# apollo4p register map
Vendor: Ambiq Micro; Series: Apollo; File version: 1.0
CPU: CM4 r1p0, little endian, MPU, FPU, 3 interrupt priority bits
Registers are 32-bit, read-write, reset 0x0 unless marked. A register's access mark holds for its fields unless they carry their own. Offsets are from the block's base; [hi:lo] are bit positions; {n}, {i} and the like mark numbered series; 'fields as' and 'values as' point back to an identical list.

## ADC — Analog Digital Converter Control
Base 0x40038000
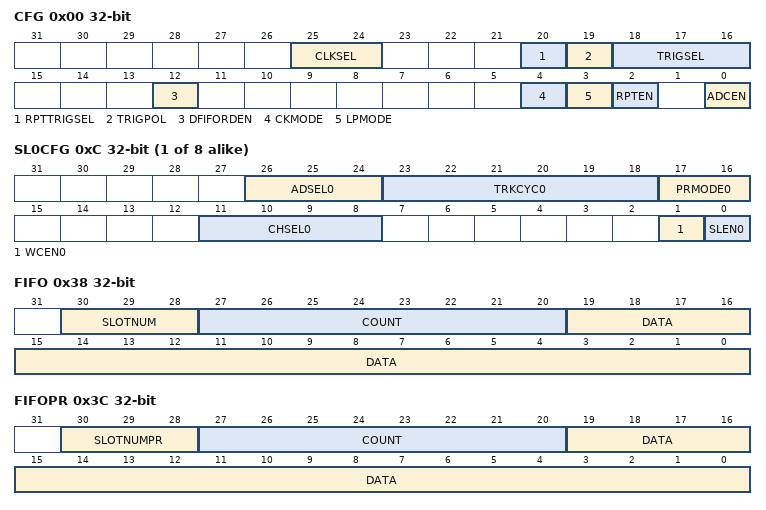
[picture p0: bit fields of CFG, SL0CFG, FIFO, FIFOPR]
0x00 CFG — The ADC Configuration Register contains the software control for selecting the clock frequency used for the SAR conversions, the trigger polarity, the trigger select, the reference voltage select, the low power mode, the operating mode (single scan per trigger vs. repeating mode) and ADC enable.
  [25:24] CLKSEL — Select the source and frequency for the ADC clock. HFRC_48MHz is the only valid clock selection and can be selected by either of 2 field values; the reset default of 0 or by the value 1. All values enumerated below as 'RESVD' are undefined. The ADC controller automatically shuts off the clock in its low power modes. When setting ADCEN to '0', CLKSEL should remain set to 0x0 or 0x1 for proper power down sequencing.
    0=HFRC_48MHZ (HFRC Clock 48MHz.); 1=HFRC_48MHZ1 (HFRC Clock 48MHz. Note that the preferred setting is HFRC_48MHZ (0).)
  [20] RPTTRIGSEL — This bit selects which periodic trigger to use with RPTEN = 1.
    0=TMR (Trigger from on-chip timer.); 1=INT (Trigger from ADC-internal timer.)
  [19] TRIGPOL — This bit selects the ADC trigger polarity for external off chip triggers.
    0=RISING_EDGE (Trigger on rising edge.); 1=FALLING_EDGE (Trigger on falling edge.)
  [18:16] TRIGSEL — Select the ADC trigger source.
    {v}=EXT{v} (Off chip External Trigger{v} (ADC_ET{v})) (v=0..3); 4=VCOMP (Voltage Comparator Output); 7=SWT (Software Trigger)
  [12] DFIFORDEN — Destructive FIFO Read Enable. Setting this will enable FIFO pop upon reading the FIFOPR register.
    0=DIS (Destructive Reads are prevented. Reads to the FIFOPR register will not POP an entry off the FIFO.); 1=EN (Reads to the FIFOPR registger will automatically pop an entry off the FIFO.)
  [4] CKMODE — Clock mode register
    0=LPCKMODE (Disable the clock between scans for LPMODE0. Set LPCKMODE to 0x1 while configuring the ADC.); 1=LLCKMODE (Low Latency Clock Mode. When set, HFRC and the adc_clk will remain on while in functioning in LPMODE0.)
  [3] LPMODE — Select power mode to enter between active scans.
    0=MODE0 (Low Power Mode 0. Leaves the ADC fully powered between scans with minimum latency between a trigger event and sample data collection.); 1=MODE1 (Low Power Mode 1. Powers down all circuity and clocks associated with the ADC until the next trigger event. Between scans, the reference buffer requires up to 50us of delay from a scan trigger event before the conversion will commence while operating in this mode.)
  [2] RPTEN — This bit enables Repeating Scan Mode.
    0=SINGLE_SCAN (In Single Scan Mode, the ADC will complete a single scan upon each trigger event.); 1=REPEATING_SCAN (In Repeating Scan Mode, the ADC will complete its first scan upon the initial trigger event and all subsequent scans will occur at regular intervals defined by the configuration programmed for the CTTMRA3 timer or the ADC-internal timer (see the RPTTRIGSEL field) until the timer is disabled or the ADC is disabled. When disabling the ADC (setting ADCEN to '0'), the RPTEN bit should be cleared.)
  [0] ADCEN — This bit enables the ADC module. While the ADC is enabled, the ADCCFG and SLOT Configuration regsiter settings must remain stable and unchanged. All configuration register settings, slot configuration settings and window comparison settings should be written prior to setting the ADCEN bit to '1'.
    0=DIS (Disable the ADC module.); 1=EN (Enable the ADC module.)
0x04 STAT — This register indicates the basic power status for the ADC. For detailed power status, see the power control power status register. ADC power mode 0 indicates the ADC is in its full power state and is ready to process scans. ADC Power mode 1 indicates the ADC enabled and in a low power state.
  [0] PWDSTAT — Indicates the power-status of the ADC.
    0=ON (Powered on.); 1=POWERED_DOWN (ADC Low Power Mode 1.)
0x08 SWT — This register enables initiating an ADC scan through software.
  [7:0] SWT — Writing 0x37 to this register generates a software trigger.
    55=GEN_SW_TRIGGER (Writing this value generates a software trigger.); 0=NO_SW_TRIGGER (Default value.)
{0xC+4i} SL{i}CFG (i=0..7) — Slot {i} Configuration
  [26:24] ADSEL{i} — Select the number of measurements to average in the accumulate divide module for this slot.
    0=AVG_1_MSRMT (Average in 1 measurement in the accumulate divide module for this slot.); 1=AVG_2_MSRMTS (Average in 2 measurements in the accumulate divide module for this slot.); 2=AVG_4_MSRMTS (Average in 4 measurements in the accumulate divide module for this slot.); 3=AVG_8_MSRMT (Average in 8 measurements in the accumulate divide module for this slot.); 4=AVG_16_MSRMTS (Average in 16 measurements in the accumulate divide module for this slot.); 5=AVG_32_MSRMTS (Average in 32 measurements in the accumulate divide module for this slot.); 6=AVG_64_MSRMTS (Average in 64 measurements in the accumulate divide module for this slot.); 7=AVG_128_MSRMTS (Average in 128 measurements in the accumulate divide module for this slot.)
  [23:18] TRKCYC{i} — Set additional input signal sampling/tracking time to the specified number of ADC clock cycles. (Note that a value of 0 in this register specifies the minimum required 5 cycles. A maximum of 64 specifies 69 cycles.)
  [17:16] PRMODE{i} — Set the Precision Mode For Slot {i}.
    0=P12B0 (12-bit precision mode); 1=P12B1 (12-bit precision mode); 2=P10B (10-bit precision mode); 3=P8B (8-bit precision mode)
  [11:8] CHSEL{i} — Select one of the 14 channel inputs for this slot.
    0=SE0 (Single ended external GPIO connection to pad16.); 1=SE1 (Single ended external GPIO connection to pad29.); 2=SE2 (Single ended external GPIO connection to pad11.); {v}=SE{v} (Single ended external GPIO connection to pad{v+28}.) (v=3..7); 8=TEMP (Internal temperature sensor.); 9=BATT (Internal voltage divide-by-3 connection.); 10=TESTMUX (Analog testmux.); 11=VSS (Input VSS.)
  [1] WCEN{i} — This bit enables the window compare function for slot {i}.
    1=WCEN (Enable the window compare for slot {i}.); 0=WCDIS (Disable the window compare for slot {i}.)
  [0] SLEN{i} — This bit enables slot {i} for ADC conversions.
    1=SLEN (Enable slot {i} for ADC conversions.); 0=SLDIS (Disable slot {i} for ADC conversions.)
0x2C WULIM — Window Comparator Upper Limits
  [19:0] ULIM — Sets the upper limit for the window comparator.
0x30 WLLIM — Window Comparator Lower Limits
  [19:0] LLIM — Sets the lower limit for the window comparator.
0x34 SCWLIM — Scale Window Comparator Limits
  [0] SCWLIMEN — Scale the window limits compare values per precision mode. When set to 0x0 (default), the values in the 20-bit limits registers will compare directly with the FIFO values regardless of the precision mode the slot is configured to. When set to 0x1, the compare values will be divided by the difference in precision bits while performing the window limit comparisons.
0x38 FIFO — The ADC FIFO Register contains the slot number and fifo data for the oldest conversion data in the FIFO. The COUNT field indicates the total number of valid entries in the FIFO. A write to this register will pop one of the FIFO entries off the FIFO and decrease the COUNT by 1 if the COUNT is greater than zero.
  [30:28] SLOTNUM — Slot number associated with this FIFO data.
  [27:20] COUNT — Number of valid entries in the ADC FIFO.
  [19:0] DATA — Oldest data in the FIFO.
0x3C FIFOPR — This is a Pop Read mirrored copy of the ADCFIFO register with the only difference being that reading this register will result in a simultaneous FIFO POP which is also achieved by writing to the ADCFIFO Register. Note: The DFIFORDEN bit must be set in the CFG register for the the destructive read to be enabled.
  [30:28] SLOTNUMPR — Slot number associated with this FIFO data.
  [27:20] COUNT — Number of valid entries in the ADC FIFO.
  [19:0] DATA — Oldest data in the FIFO.
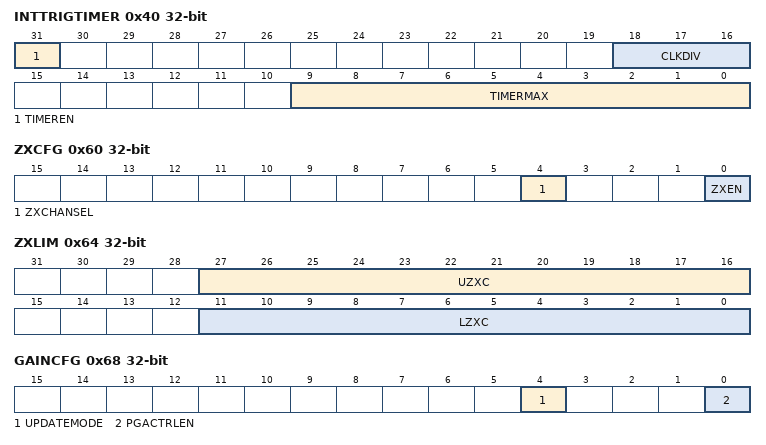
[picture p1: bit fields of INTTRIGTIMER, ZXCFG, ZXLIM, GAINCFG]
0x40 INTTRIGTIMER — ADC-Internal Repeating Trigger Timer Configuration
  [31] TIMEREN — ADC-internal trigger timer enable.
    0=DIS (Disable the ADC-internal trigger timer.); 1=EN (Enable the ADC-internal trigger timer.)
  [18:16] CLKDIV — Configure number of divide-by-2 of clock source as input to trigger counter. (Max value of 5.) A value of 0 in this register would not divide down the ADC input clock. A value of 1 would divide the ADC input clock frequency by 2. A value of 5 would divide the ADC input clock frequency by 2^5 = 32. To update this value, first disable the INTTRIGTIMER by setting TIMEREN to DIS, change CLKDIV, and then reenable it INTTRIGTIMER by setting TIMEREN to EN again.
  [9:0] TIMERMAX — Trigger counter count max, used as initial condition to trigger. Also used repeatedly each time counter reaches it to restart trigger timer at zero. To update this value, first disable the INTTRIGTIMER by setting TIMEREN to DIS, change TIMERMAX, and then reenable it INTTRIGTIMER by setting TIMEREN to EN again.
0x60 ZXCFG — Zero Crossing Comparator Configuration
  [4] ZXCHANSEL — Select which slots to use for zero crossing measurement. 0 enables zero crossing detection on slots 0 and 2. 1 enables zero crossing detection on slots 1 and 3.
  [0] ZXEN — Enable the ZX comparator
0x64 ZXLIM — Zero Crossing Comparator Limits
  [27:16] UZXC — Sets the upper integer sample limit for the ZX comparator. Note that these values are raw ADC values whose bounds are specified by PRMODE but not maniupulated by accumulate/divide logic. Therefore, there is no oversampling and no binary point in this value. Samples must enter the range between UZXC and LZXC in order for a zero crossing to be recognized.
  [11:0] LZXC — Sets the lower integer sample limit for the ZX comparator. Note that these values are raw ADC values whose bounds are specified by PRMODE but not maniupulated by accumulate/divide logic. Therefore, there is no oversampling and no binary point in this value. Samples must enter the range between UZXC and LZXC in order for a zero crossing to be recognized.
0x68 GAINCFG — PGA Gain Configuration
  [4] UPDATEMODE — PGA update mode
    0=IMMED (Immediate update mode. Once gain is written, it is immediately encoded and provided to the PGA.); 1=ZX (Update gain only at detected zero crossing as configured by ZX registers.)
  [0] PGACTRLEN — Enable PGA gain updates.
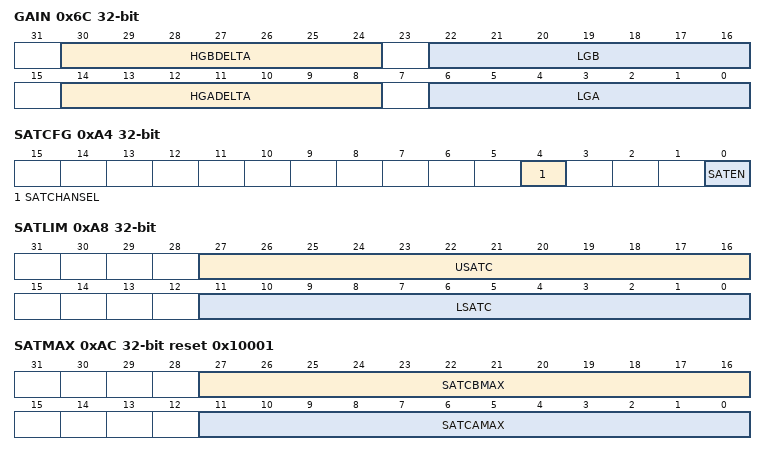
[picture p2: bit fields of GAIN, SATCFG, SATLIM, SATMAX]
0x6C GAIN — PGA Gain Codes
  [30:24] HGBDELTA — Specifies the high gain code as an delta from the LGB field for channel B (slot 3).
  [22:16] LGB — Specifies the low gain code (0 to 102 decimal specifies -6.0 dB to 45.0 dB in half-dB increments) for channel B (slot 2).
  [14:8] HGADELTA — Specifies the high gain code as an delta from the LGA field for channel A (slot 1).
  [6:0] LGA — Specifies the low gain code (0 to 102 decimal specifies -6.0 dB to 45.0 dB in half-dB increments) for channel A (slot 0).
0xA4 SATCFG — Saturation Comparator Configuration
  [4] SATCHANSEL — Select which slots to use for saturation measurement. 0 enables saturation on slots 0 and 2. 1 enables saturation on slots 1 and 3.
  [0] SATEN — Enable the saturation comparator
0xA8 SATLIM — Saturation Comparator Limits
  [27:16] USATC — Sets the upper integer sample limit for the saturation comparator. Note that these values are raw ADC values whose bounds are specified by PRMODE but not manipulated by accumulate/divide logic. Therefore, there is no oversampling and no binary point in this value.
  [11:0] LSATC — Sets the lower integer sample limit for the saturation comparator. Note that these values are raw ADC values whose bounds are specified by PRMODE but not manipulated by accumulate/divide logic. Therefore, there is no oversampling and no binary point in this value.
0xAC SATMAX reset 0x10001 — Saturation Comparator Event Counter Limits
  [27:16] SATCBMAX — Sets the number of saturation events that may occur before a SATCB interrupt occurs. Once this interrupt occurs, the saturation event counter must be cleared by writing the SATCLR register. A value of 0 is invalid and will cause the saturation interrupt to assert immediately.
  [11:0] SATCAMAX — Sets the number of saturation events that may occur before a SATCA interrupt occurs. Once this interrupt occurs, the saturation event counter must be cleared by writing the SATCLR register. A value of 0 is invalid and will cause the saturation interrupt to assert immediately.
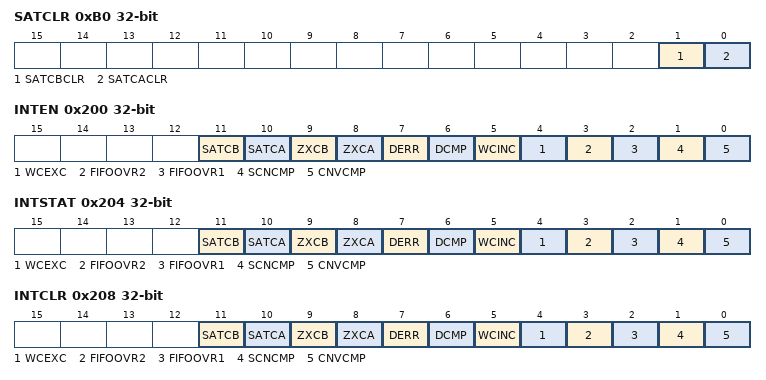
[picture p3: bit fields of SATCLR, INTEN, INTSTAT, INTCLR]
0xB0 SATCLR — Clears the saturation event counter registers
  [1] SATCBCLR — Clear saturation event counter register for channel B (slots 2 or 3, depending on SATCHANSEL)
  [0] SATCACLR — Clear saturation event counter register for channel A (slots 0 or 1, depending on SATCHANSEL)
0x200 INTEN — Set bits in this register to allow this module to generate the corresponding interrupt.
  [11] SATCB — Saturation - Channel B (Slots 2 or 3)
    1=SATCBINT (Saturation, as specified by SAT configuration registers, occurred on either slot 2 or 3 (channel B)); 0=NONSATCBINT (No-Saturation)
  [10] SATCA — Saturation - Channel A (Slots 0 or 1)
    1=SATCAINT (Saturation, as specified by SAT configuration registers, occurred on either slot 0 or 1 (channel A)); 0=NONSATCAINT (No Saturation)
  [9] ZXCB — Zero Crossing - Channel B (Slots 2 or 3)
    1=ZXCBINT (Zero Crossing, as specified by ZX configuration registers, occurred on either slot 2 or 3 (channel B)); 0=NONZXCBINT (Non Zero Crossing)
  [8] ZXCA — Zero Crossing - Channel A (Slots 0 or 1)
    1=ZXCAINT (Zero Crossing, as specified by ZX configuration registers, occurred on either slot 0 or 1 (channel A)); 0=NONZXCAINT (Non Zero Crossing)
  [7] DERR — DMA Error Condition
    1=DMAERROR (DMA Error Condition Occurred); 0=NODMAERROR (DMA Error Condition did not Occurred)
  [6] DCMP — DMA Transfer Complete
    1=DMACOMPLETE (DMA Completed a transfer); 0=DMAON (DMA completion is pending or not triggered.)
  [5] WCINC — Window comparator voltage incursion interrupt.
    1=WCINCINT (Window comparator voltage incursion interrupt.); 0=WCINCNOINT (Not a Window comparator voltage incursion interrupt.)
  [4] WCEXC — Window comparator voltage excursion interrupt.
    1=WCEXCINT (Window comparator voltage excursion interrupt.); 0=WCEXCNOINT (Not a Window comparator voltage excursion interrupt.)
  [3] FIFOOVR2 — FIFO 100 percent full interrupt.
    1=FIFOFULLINT (FIFO 100 percent full interrupt.); 0=FIFOFULLNOINT (Not a FIFO 100 percent full interrupt.)
  [2] FIFOOVR1 — FIFO 75 percent full interrupt.
    1=FIFO75INT (FIFO 75 percent full interrupt.); 0=FIFO75NOINT (Not FIFO 75 percent full interrupt.)
  [1] SCNCMP — ADC scan complete interrupt.
    1=SCNCMPINT (ADC scan complete interrupt.); 0=SCNCMPNOINT (No ADC scan complete interrupt.)
  [0] CNVCMP — ADC conversion complete interrupt.
    1=CNVCMPINT (ADC conversion complete interrupt.); 0=CNVCMPNOINT (No ADC conversion complete interrupt.)
0x204 INTSTAT — Read bits from this register to discover the cause of a recent interrupt.
  fields as INTEN
0x208 INTCLR — Write a 1 to a bit in this register to clear the interrupt status associated with that bit.
  fields as INTEN
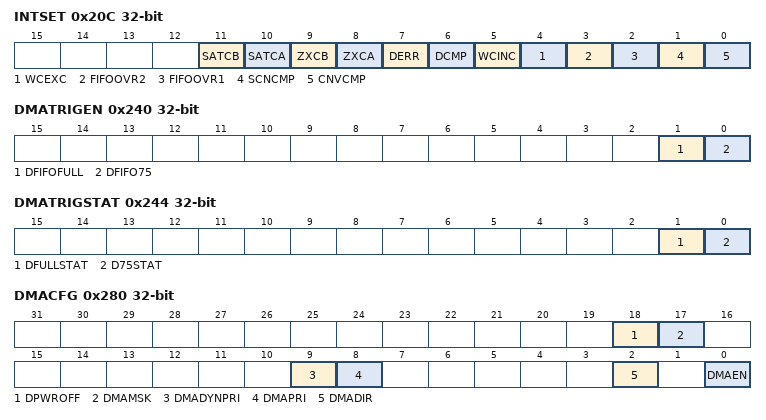
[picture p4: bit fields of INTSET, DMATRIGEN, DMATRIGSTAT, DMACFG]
0x20C INTSET — Write a 1 to a bit in this register to instantly generate an interrupt from this module. (Generally used for testing purposes).
  fields as INTEN
0x240 DMATRIGEN — DMA Trigger Enable
  [1] DFIFOFULL — Trigger DMA upon FIFO 100 percent Full
  [0] DFIFO75 — Trigger DMA upon FIFO 75 percent Full
0x244 DMATRIGSTAT — DMA Trigger Status
  [1] DFULLSTAT — Triggered DMA from FIFO 100 percent Full
  [0] D75STAT — Triggered DMA from FIFO 75 percent Full
0x280 DMACFG — DMA Configuration
  [18] DPWROFF — Power Off the ADC System upon DMACPL.
  [17] DMAMSK — Mask the FIFOCNT and SLOTNUM when transferring FIFO contents to memory
    0=DIS (FIFO Contents are copied directly to memory without modification.); 1=EN (Only the FIFODATA contents are copied to memory on DMA transfers. The SLOTNUM and FIFOCNT contents are cleared to zero.)
  [9] DMADYNPRI — Enables dynamic priority based on FIFO fullness. When FIFO is full, priority is automatically set to HIGH. Otherwise, DMAPRI is used.
    0=DIS (Disable dynamic priority (use DMAPRI setting only)); 1=EN (Enable dynamic priority)
  [8] DMAPRI — Sets the Priority of the DMA request
    0=LOW (Low Priority (service as best effort)); 1=HIGH (High Priority (service immediately))
  [2] DMADIR — Direction
    0=P2M (Peripheral to Memory (SRAM) transaction); 1=M2P (Memory to Peripheral transaction)
  [0] DMAEN — DMA Enable
    0=DIS (Disable DMA Function); 1=EN (Enable DMA Function)
0x288 DMATOTCOUNT — DMA Total Transfer Count
  [17:2] TOTCOUNT — Total Transfer Count
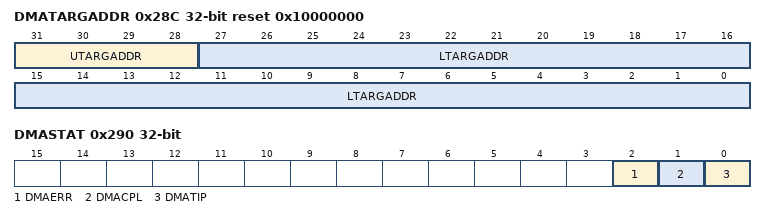
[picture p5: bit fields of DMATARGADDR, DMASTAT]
0x28C DMATARGADDR reset 0x10000000 — DMA Target Address
  [31:28] UTARGADDR — SRAM Target
  [27:0] LTARGADDR — DMA Target Address
0x290 DMASTAT — DMA Status
  [2] DMAERR — DMA Error
  [1] DMACPL — DMA Transfer Complete
  [0] DMATIP — DMA Transfer In Progress

## Notices in the file
Copyright (C) 2012-2014 ARM Limited. All rights reserved.
Purpose: System Viewer Description (SVD) Example (Schema Version 1.1)
This is a description of a none-existent and incomplete device
for demonstration purposes only.
Redistribution and use in source and binary forms, with or without
modification, are permitted provided that the following conditions are met:
- Redistributions of source code must retain the above copyright
notice, this list of conditions and the following disclaimer.
- Redistributions in binary form must reproduce the above copyright
notice, this list of conditions and the following disclaimer in the
documentation and/or other materials provided with the distribution.
- Neither the name of ARM nor the names of its contributors may be used
to endorse or promote products derived from this software without
specific prior written permission.
THIS SOFTWARE IS PROVIDED BY THE COPYRIGHT HOLDERS AND CONTRIBUTORS "AS IS"
AND ANY EXPRESS OR IMPLIED WARRANTIES, INCLUDING, BUT NOT LIMITED TO, THE
IMPLIED WARRANTIES OF MERCHANTABILITY AND FITNESS FOR A PARTICULAR PURPOSE
ARE DISCLAIMED. IN NO EVENT SHALL COPYRIGHT HOLDERS AND CONTRIBUTORS BE
LIABLE FOR ANY DIRECT, INDIRECT, INCIDENTAL, SPECIAL, EXEMPLARY, OR
CONSEQUENTIAL DAMAGES (INCLUDING, BUT NOT LIMITED TO, PROCUREMENT OF
SUBSTITUTE GOODS OR SERVICES; LOSS OF USE, DATA, OR PROFITS; OR BUSINESS
INTERRUPTION) HOWEVER CAUSED AND ON ANY THEORY OF LIABILITY, WHETHER IN
CONTRACT, STRICT LIABILITY, OR TORT (INCLUDING NEGLIGENCE OR OTHERWISE)
ARISING IN ANY WAY OUT OF THE USE OF THIS SOFTWARE, EVEN IF ADVISED OF THE
POSSIBILITY OF SUCH DAMAGE.
